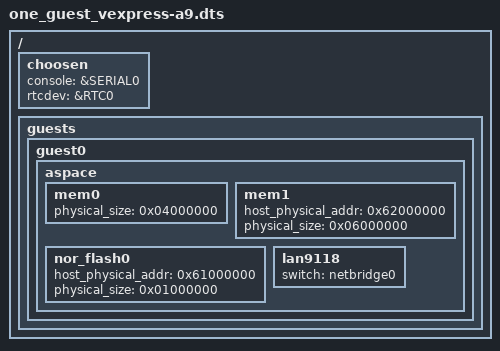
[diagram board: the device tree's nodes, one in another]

/dts-v1/;

/include/ "vexpress-a9.dtsi"

/include/ "../../../common/guests/one_guest_vexpress-a9x2.dtsi"

/ {
	choosen {
		console = &SERIAL0;
		rtcdev = &RTC0;
	};

	guests {
		guest0 {
			aspace {
				mem0 {
					physical_size = <0x04000000>; /* 64 MB */
				};

				mem1 {
					host_physical_addr = <0x62000000>;
					physical_size = <0x06000000>; /* 96 MB */
				};

				nor_flash0 {
					host_physical_addr = <0x61000000>;
					physical_size = <0x01000000>; /* 16 MB */
				};

				lan9118 {
					switch = "netbridge0";
				};
			};
		};
	};
};
